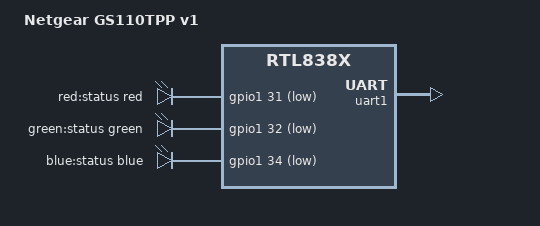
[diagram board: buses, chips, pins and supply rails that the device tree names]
// SPDX-License-Identifier: GPL-2.0-or-later

#include "rtl8380_netgear_gigabit_1xx.dtsi"
#include <dt-bindings/leds/common.h>

/ {
	compatible = "netgear,gs110tpp-v1", "realtek,rtl838x-soc";
	model = "Netgear GS110TPP v1";

	aliases {
		led-boot = &led_status_green;
		led-failsafe = &led_status_red;
		led-running = &led_status_green;
		led-upgrade = &led_status_blue;
	};

	leds {
		compatible = "gpio-leds";

		led_status_red: led-0 {
			label = "red:status";
			color = <LED_COLOR_ID_RED>;
			function = LED_FUNCTION_STATUS;
			gpios = <&gpio1 31 GPIO_ACTIVE_LOW>;
		};

		led_status_green: led-1 {
			label = "green:status";
			color = <LED_COLOR_ID_GREEN>;
			function = LED_FUNCTION_STATUS;
			gpios = <&gpio1 32 GPIO_ACTIVE_LOW>;
		};

		led_status_blue: led-2 {
			label = "blue:status";
			color = <LED_COLOR_ID_BLUE>;
			function = LED_FUNCTION_STATUS;
			gpios = <&gpio1 34 GPIO_ACTIVE_LOW>;
		};
	};
};

&uart1 {
	status = "okay";
};
